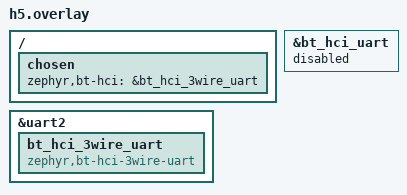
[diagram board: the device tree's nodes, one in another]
/ {
	chosen {
		zephyr,bt-hci = &bt_hci_3wire_uart;
	};
};

&bt_hci_uart {
	status = "disabled";
};

&uart2 {
	bt_hci_3wire_uart: bt_hci_3wire_uart {
		compatible = "zephyr,bt-hci-3wire-uart";
		status = "okay";
	};
};
